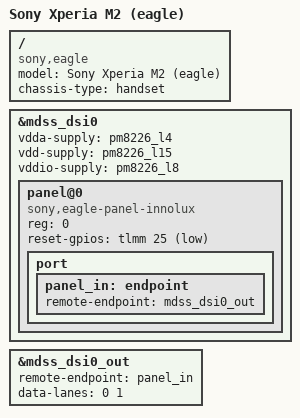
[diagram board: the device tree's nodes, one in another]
// SPDX-License-Identifier: BSD-3-Clause
/*
 * Copyright (c) 2025, Giovanni Ricca <giovanniricca@proton.me>
 */

#include "msm8926.dtsi"
#include "qcom-msm8226-sony-xperia-yukon.dtsi"

#include <dt-bindings/arm/qcom,ids.h>

/ {
	model = "Sony Xperia M2 (eagle)";
	compatible = "sony,eagle", "qcom,msm8926", "qcom,msm8226";
	chassis-type = "handset";
};

&mdss_dsi0 {
	vdda-supply = <&pm8226_l4>;
	vdd-supply = <&pm8226_l15>;
	vddio-supply = <&pm8226_l8>;

	panel@0 {
		compatible = "sony,eagle-panel-innolux";
		reg = <0>;

		reset-gpios = <&tlmm 25 GPIO_ACTIVE_LOW>;

		port {
			panel_in: endpoint {
				remote-endpoint = <&mdss_dsi0_out>;
			};
		};
	};
};

&mdss_dsi0_out {
	remote-endpoint = <&panel_in>;
	data-lanes = <0 1>;
};
